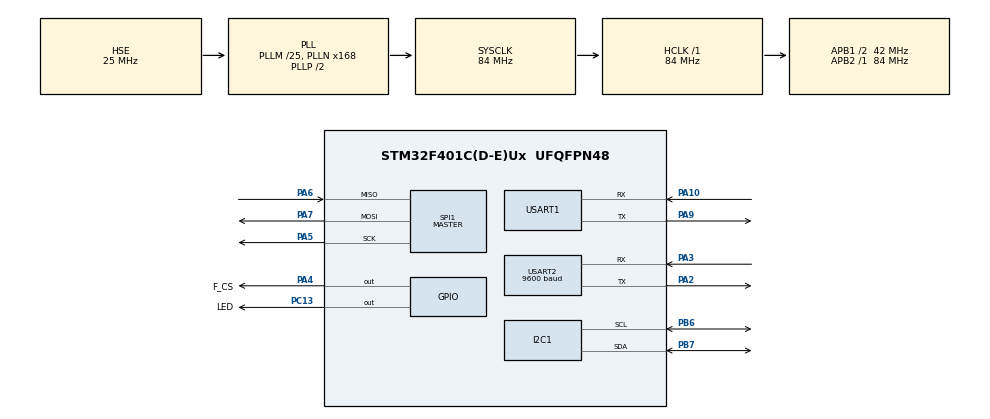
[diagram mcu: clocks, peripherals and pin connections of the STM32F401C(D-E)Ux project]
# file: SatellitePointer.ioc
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Dma.Request0=USART2_RX
Dma.USART2_RX.0.Direction=DMA_PERIPH_TO_MEMORY
Dma.USART2_RX.0.FIFOMode=DMA_FIFOMODE_DISABLE
Dma.USART2_RX.0.Instance=DMA1_Stream5
Dma.USART2_RX.0.MemDataAlignment=DMA_MDATAALIGN_BYTE
Dma.USART2_RX.0.MemInc=DMA_MINC_ENABLE
Dma.USART2_RX.0.Mode=DMA_NORMAL
Dma.USART2_RX.0.PeriphDataAlignment=DMA_PDATAALIGN_BYTE
Dma.USART2_RX.0.PeriphInc=DMA_PINC_DISABLE
Dma.USART2_RX.0.Priority=DMA_PRIORITY_LOW
FREERTOS.Tasks01=defaultTask,24,512,StartDefaultTask,Default,NULL,Dynamic,NULL,NULL;myTask01,8,256,StartTask01,Default,NULL,Dynamic,NULL,NULL;myTask02,8,256,StartTask02,Default,NULL,Dynamic,NULL,NULL
FREERTOS.Timers01=myTimer01,Callback01,osTimerPeriodic,Default,NULL,Dynamic,NULL;myTimer02,Callback02,osTimerPeriodic,Default,NULL,Dynamic,NULL;myTimer03,Callback03,osTimerPeriodic,Default,NULL,Dynamic,NULL;myTimer04,Callback04,osTimerPeriodic,Default,NULL,Dynamic,NULL
FREERTOS.configENABLE_FPU=1
FREERTOS.configMINIMAL_STACK_SIZE=256
FREERTOS.configTIMER_TASK_STACK_DEPTH=1024
FREERTOS.configUSE_NEWLIB_REENTRANT=1
I2C1.I2C_Mode=I2C_Fast
Mcu.Family=STM32F4
Mcu.Name=STM32F401C(D-E)Ux
Mcu.Package=UFQFPN48
NVIC.DMA1_Stream5_IRQn=true\:5\:0\:false\:false\:true\:true\:false\:true\:true
NVIC.PriorityGroup=NVIC_PRIORITYGROUP_4
NVIC.TIM1_UP_TIM10_IRQn=true\:15\:0\:false\:false\:true\:false\:false\:true\:true
NVIC.TimeBase=TIM1_UP_TIM10_IRQn
NVIC.TimeBaseIP=TIM1
NVIC.USART2_IRQn=true\:5\:0\:false\:false\:true\:true\:true\:true\:true
PA10.Mode=Asynchronous
PA10.Signal=USART1_RX
PA13.Mode=Serial_Wire
PA13.Signal=SYS_JTMS-SWDIO
PA14.Mode=Serial_Wire
PA14.Signal=SYS_JTCK-SWCLK
PA2.Mode=Asynchronous
PA2.Signal=USART2_TX
PA3.Mode=Asynchronous
PA3.Signal=USART2_RX
PA4.GPIO_Label=F_CS
PA4.GPIO_Speed=GPIO_SPEED_FREQ_VERY_HIGH
PA4.PinState=GPIO_PIN_RESET
PA4.Signal=GPIO_Output
PA5.Mode=Full_Duplex_Master
PA5.Signal=SPI1_SCK
PA6.Mode=Full_Duplex_Master
PA6.Signal=SPI1_MISO
PA7.Mode=Full_Duplex_Master
PA7.Signal=SPI1_MOSI
PA9.Mode=Asynchronous
PA9.Signal=USART1_TX
PB6.Mode=I2C
PB6.Signal=I2C1_SCL
PB7.Mode=I2C
PB7.Signal=I2C1_SDA
PC13-ANTI_TAMP.GPIO_Label=LED
PC13-ANTI_TAMP.Signal=GPIO_Output
PC14-OSC32_IN.Mode=LSE-External-Oscillator
PC14-OSC32_IN.Signal=RCC_OSC32_IN
PC15-OSC32_OUT.Mode=LSE-External-Oscillator
PC15-OSC32_OUT.Signal=RCC_OSC32_OUT
PH0\ -\ OSC_IN.Mode=HSE-External-Oscillator
PH0\ -\ OSC_IN.Signal=RCC_OSC_IN
PH1\ -\ OSC_OUT.Mode=HSE-External-Oscillator
PH1\ -\ OSC_OUT.Signal=RCC_OSC_OUT
ProjectManager.HeapSize=0x200
ProjectManager.StackSize=0x400
ProjectManager.TargetToolchain=STM32CubeIDE
RCC.48MHZClocksFreq_Value=42000000
RCC.AHBFreq_Value=84000000
RCC.APB1CLKDivider=RCC_HCLK_DIV2
RCC.APB1Freq_Value=42000000
RCC.APB1TimFreq_Value=84000000
RCC.APB2Freq_Value=84000000
RCC.APB2TimFreq_Value=84000000
RCC.CortexFreq_Value=84000000
RCC.HCLKFreq_Value=84000000
RCC.HSE_VALUE=25000000
RCC.HSI_VALUE=16000000
RCC.PLLM=25
RCC.PLLN=168
RCC.PLLSourceVirtual=RCC_PLLSOURCE_HSE
RCC.RCC_RTC_Clock_Source=RCC_RTCCLKSOURCE_LSE
RCC.RCC_RTC_Clock_SourceVirtual=RCC_RTCCLKSOURCE_LSE
RCC.SYSCLKFreq_VALUE=84000000
RCC.SYSCLKSource=RCC_SYSCLKSOURCE_PLLCLK
RCC.VCOOutputFreq_Value=168000000
SPI1.CLKPhase=SPI_PHASE_2EDGE
SPI1.CLKPolarity=SPI_POLARITY_HIGH
SPI1.Direction=SPI_DIRECTION_2LINES
SPI1.Mode=SPI_MODE_MASTER
SPI1.VirtualType=VM_MASTER
USART1.VirtualMode=VM_ASYNC
USART2.BaudRate=9600
USART2.VirtualMode=VM_ASYNC
VP_FREERTOS_VS_CMSIS_V2.Mode=CMSIS_V2
VP_RTC_VS_RTC_Activate.Mode=RTC_Enabled
VP_SYS_VS_tim1.Mode=TIM1
board=custom

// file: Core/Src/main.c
/* USER CODE BEGIN Header */
/**
  ******************************************************************************
  * @file           : main.c
  * @brief          : Main program body
  ******************************************************************************
  * @attention
  *
  * Copyright (c) 2023 STMicroelectronics.
  * All rights reserved.
  *
  * This software is licensed under terms that can be found in the LICENSE file
  * in the root directory of this software component.
  * If no LICENSE file comes with this software, it is provided AS-IS.
  *
  ******************************************************************************
  */
/* USER CODE END Header */
#include "main.h"
#include "cmsis_os.h"

I2C_HandleTypeDef hi2c1;

RTC_HandleTypeDef hrtc;

SPI_HandleTypeDef hspi1;

UART_HandleTypeDef huart1;
UART_HandleTypeDef huart2;
DMA_HandleTypeDef hdma_usart2_rx;

/* Definitions for defaultTask */
osThreadId_t defaultTaskHandle;
const osThreadAttr_t defaultTask_attributes = {
  .name = "defaultTask",
  .stack_size = 512 * 4,
  .priority = (osPriority_t) osPriorityNormal,
};
/* Definitions for myTask01 */
osThreadId_t myTask01Handle;
const osThreadAttr_t myTask01_attributes = {
  .name = "myTask01",
  .stack_size = 256 * 4,
  .priority = (osPriority_t) osPriorityLow,
};
/* Definitions for myTask02 */
osThreadId_t myTask02Handle;
const osThreadAttr_t myTask02_attributes = {
  .name = "myTask02",
  .stack_size = 256 * 4,
  .priority = (osPriority_t) osPriorityLow,
};
/* Definitions for myTimer01 */
osTimerId_t myTimer01Handle;
const osTimerAttr_t myTimer01_attributes = {
  .name = "myTimer01"
};
/* Definitions for myTimer02 */
osTimerId_t myTimer02Handle;
const osTimerAttr_t myTimer02_attributes = {
  .name = "myTimer02"
};
/* Definitions for myTimer03 */
osTimerId_t myTimer03Handle;
const osTimerAttr_t myTimer03_attributes = {
  .name = "myTimer03"
};
/* Definitions for myTimer04 */
osTimerId_t myTimer04Handle;
const osTimerAttr_t myTimer04_attributes = {
  .name = "myTimer04"
};

void SystemClock_Config(void);
static void MX_GPIO_Init(void);
static void MX_DMA_Init(void);
static void MX_I2C1_Init(void);
static void MX_SPI1_Init(void);
static void MX_USART1_UART_Init(void);
static void MX_USART2_UART_Init(void);
static void MX_RTC_Init(void);
void StartDefaultTask(void *argument);
void StartTask01(void *argument);
void StartTask02(void *argument);
void Callback01(void *argument);
void Callback02(void *argument);
void Callback03(void *argument);
void Callback04(void *argument);

int main(void)
{

  /* MCU Configuration--------------------------------------------------------*/

  /* Reset of all peripherals, Initializes the Flash interface and the Systick. */
  HAL_Init();

  /* Configure the system clock */
  SystemClock_Config();

  /* Initialize all configured peripherals */
  MX_GPIO_Init();
  MX_DMA_Init();
  MX_I2C1_Init();
  MX_SPI1_Init();
  MX_USART1_UART_Init();
  MX_USART2_UART_Init();
  MX_RTC_Init();

  /* Init scheduler */
  osKernelInitialize();

  /* Create the timer(s) */
  /* creation of myTimer01 */
  myTimer01Handle = osTimerNew(Callback01, osTimerPeriodic, NULL, &myTimer01_attributes);

  /* creation of myTimer02 */
  myTimer02Handle = osTimerNew(Callback02, osTimerPeriodic, NULL, &myTimer02_attributes);

  /* creation of myTimer03 */
  myTimer03Handle = osTimerNew(Callback03, osTimerPeriodic, NULL, &myTimer03_attributes);

  /* creation of myTimer04 */
  myTimer04Handle = osTimerNew(Callback04, osTimerPeriodic, NULL, &myTimer04_attributes);

  /* USER CODE BEGIN RTOS_TIMERS */
  /* start timers, add new ones, ... */
  osTimerStart(myTimer01Handle, 1000);
  osTimerStart(myTimer02Handle, 10);
  /* USER CODE END RTOS_TIMERS */

  /* Create the thread(s) */
  /* creation of defaultTask */
  defaultTaskHandle = osThreadNew(StartDefaultTask, NULL, &defaultTask_attributes);

  /* creation of myTask01 */
  myTask01Handle = osThreadNew(StartTask01, NULL, &myTask01_attributes);

  /* creation of myTask02 */
  myTask02Handle = osThreadNew(StartTask02, NULL, &myTask02_attributes);

  /* Start scheduler */
  osKernelStart();
  /* We should never get here as control is now taken by the scheduler */
  /* Infinite loop */
  while (1)
  {

  }
}

void SystemClock_Config(void)
{
  RCC_OscInitTypeDef RCC_OscInitStruct = {0};
  RCC_ClkInitTypeDef RCC_ClkInitStruct = {0};

  /** Configure the main internal regulator output voltage
  */
  __HAL_RCC_PWR_CLK_ENABLE();
  __HAL_PWR_VOLTAGESCALING_CONFIG(PWR_REGULATOR_VOLTAGE_SCALE2);

  /** Initializes the RCC Oscillators according to the specified parameters
  * in the RCC_OscInitTypeDef structure.
  */
  RCC_OscInitStruct.OscillatorType = RCC_OSCILLATORTYPE_HSE|RCC_OSCILLATORTYPE_LSE;
  RCC_OscInitStruct.HSEState = RCC_HSE_ON;
  RCC_OscInitStruct.LSEState = RCC_LSE_ON;
  RCC_OscInitStruct.PLL.PLLState = RCC_PLL_ON;
  RCC_OscInitStruct.PLL.PLLSource = RCC_PLLSOURCE_HSE;
  RCC_OscInitStruct.PLL.PLLM = 25;
  RCC_OscInitStruct.PLL.PLLN = 168;
  RCC_OscInitStruct.PLL.PLLP = RCC_PLLP_DIV2;
  RCC_OscInitStruct.PLL.PLLQ = 4;
  if (HAL_RCC_OscConfig(&RCC_OscInitStruct) != HAL_OK)
  {
    Error_Handler();
  }

  /** Initializes the CPU, AHB and APB buses clocks
  */
  RCC_ClkInitStruct.ClockType = RCC_CLOCKTYPE_HCLK|RCC_CLOCKTYPE_SYSCLK
                              |RCC_CLOCKTYPE_PCLK1|RCC_CLOCKTYPE_PCLK2;
  RCC_ClkInitStruct.SYSCLKSource = RCC_SYSCLKSOURCE_PLLCLK;
  RCC_ClkInitStruct.AHBCLKDivider = RCC_SYSCLK_DIV1;
  RCC_ClkInitStruct.APB1CLKDivider = RCC_HCLK_DIV2;
  RCC_ClkInitStruct.APB2CLKDivider = RCC_HCLK_DIV1;

  if (HAL_RCC_ClockConfig(&RCC_ClkInitStruct, FLASH_LATENCY_2) != HAL_OK)
  {
    Error_Handler();
  }
}

static void MX_I2C1_Init(void)
{

  hi2c1.Instance = I2C1;
  hi2c1.Init.ClockSpeed = 400000;
  hi2c1.Init.DutyCycle = I2C_DUTYCYCLE_2;
  hi2c1.Init.OwnAddress1 = 0;
  hi2c1.Init.AddressingMode = I2C_ADDRESSINGMODE_7BIT;
  hi2c1.Init.DualAddressMode = I2C_DUALADDRESS_DISABLE;
  hi2c1.Init.OwnAddress2 = 0;
  hi2c1.Init.GeneralCallMode = I2C_GENERALCALL_DISABLE;
  hi2c1.Init.NoStretchMode = I2C_NOSTRETCH_DISABLE;
  if (HAL_I2C_Init(&hi2c1) != HAL_OK)
  {
    Error_Handler();
  }

}

static void MX_RTC_Init(void)
{

  /** Initialize RTC Only
  */
  hrtc.Instance = RTC;
  hrtc.Init.HourFormat = RTC_HOURFORMAT_24;
  hrtc.Init.AsynchPrediv = 127;
  hrtc.Init.SynchPrediv = 255;
  hrtc.Init.OutPut = RTC_OUTPUT_DISABLE;
  hrtc.Init.OutPutPolarity = RTC_OUTPUT_POLARITY_HIGH;
  hrtc.Init.OutPutType = RTC_OUTPUT_TYPE_OPENDRAIN;
  if (HAL_RTC_Init(&hrtc) != HAL_OK)
  {
    Error_Handler();
  }

}

static void MX_SPI1_Init(void)
{

  /* SPI1 parameter configuration*/
  hspi1.Instance = SPI1;
  hspi1.Init.Mode = SPI_MODE_MASTER;
  hspi1.Init.Direction = SPI_DIRECTION_2LINES;
  hspi1.Init.DataSize = SPI_DATASIZE_8BIT;
  hspi1.Init.CLKPolarity = SPI_POLARITY_HIGH;
  hspi1.Init.CLKPhase = SPI_PHASE_2EDGE;
  hspi1.Init.NSS = SPI_NSS_SOFT;
  hspi1.Init.BaudRatePrescaler = SPI_BAUDRATEPRESCALER_2;
  hspi1.Init.FirstBit = SPI_FIRSTBIT_MSB;
  hspi1.Init.TIMode = SPI_TIMODE_DISABLE;
  hspi1.Init.CRCCalculation = SPI_CRCCALCULATION_DISABLE;
  hspi1.Init.CRCPolynomial = 10;
  if (HAL_SPI_Init(&hspi1) != HAL_OK)
  {
    Error_Handler();
  }

}

static void MX_USART1_UART_Init(void)
{

  huart1.Instance = USART1;
  huart1.Init.BaudRate = 115200;
  huart1.Init.WordLength = UART_WORDLENGTH_8B;
  huart1.Init.StopBits = UART_STOPBITS_1;
  huart1.Init.Parity = UART_PARITY_NONE;
  huart1.Init.Mode = UART_MODE_TX_RX;
  huart1.Init.HwFlowCtl = UART_HWCONTROL_NONE;
  huart1.Init.OverSampling = UART_OVERSAMPLING_16;
  if (HAL_UART_Init(&huart1) != HAL_OK)
  {
    Error_Handler();
  }

}

static void MX_USART2_UART_Init(void)
{

  huart2.Instance = USART2;
  huart2.Init.BaudRate = 9600;
  huart2.Init.WordLength = UART_WORDLENGTH_8B;
  huart2.Init.StopBits = UART_STOPBITS_1;
  huart2.Init.Parity = UART_PARITY_NONE;
  huart2.Init.Mode = UART_MODE_TX_RX;
  huart2.Init.HwFlowCtl = UART_HWCONTROL_NONE;
  huart2.Init.OverSampling = UART_OVERSAMPLING_16;
  if (HAL_UART_Init(&huart2) != HAL_OK)
  {
    Error_Handler();
  }

}

static void MX_DMA_Init(void)
{

  /* DMA controller clock enable */
  __HAL_RCC_DMA1_CLK_ENABLE();

  /* DMA interrupt init */
  /* DMA1_Stream5_IRQn interrupt configuration */
  HAL_NVIC_SetPriority(DMA1_Stream5_IRQn, 5, 0);
  HAL_NVIC_EnableIRQ(DMA1_Stream5_IRQn);

}

static void MX_GPIO_Init(void)
{
  GPIO_InitTypeDef GPIO_InitStruct = {0};

  /* GPIO Ports Clock Enable */
  __HAL_RCC_GPIOC_CLK_ENABLE();
  __HAL_RCC_GPIOH_CLK_ENABLE();
  __HAL_RCC_GPIOA_CLK_ENABLE();
  __HAL_RCC_GPIOB_CLK_ENABLE();

  /*Configure GPIO pin Output Level */
  HAL_GPIO_WritePin(LED_GPIO_Port, LED_Pin, GPIO_PIN_RESET);

  /*Configure GPIO pin Output Level */
  HAL_GPIO_WritePin(F_CS_GPIO_Port, F_CS_Pin, GPIO_PIN_RESET);

  /*Configure GPIO pin : LED_Pin */
  GPIO_InitStruct.Pin = LED_Pin;
  GPIO_InitStruct.Mode = GPIO_MODE_OUTPUT_PP;
  GPIO_InitStruct.Pull = GPIO_NOPULL;
  GPIO_InitStruct.Speed = GPIO_SPEED_FREQ_LOW;
  HAL_GPIO_Init(LED_GPIO_Port, &GPIO_InitStruct);

  /*Configure GPIO pin : F_CS_Pin */
  GPIO_InitStruct.Pin = F_CS_Pin;
  GPIO_InitStruct.Mode = GPIO_MODE_OUTPUT_PP;
  GPIO_InitStruct.Pull = GPIO_NOPULL;
  GPIO_InitStruct.Speed = GPIO_SPEED_FREQ_VERY_HIGH;
  HAL_GPIO_Init(F_CS_GPIO_Port, &GPIO_InitStruct);

}

void StartDefaultTask(void *argument)
{
  /* USER CODE BEGIN 5 */
  /* Infinite loop */
  for(;;)
  {
    osDelay(1000);
  }
  /* USER CODE END 5 */
}

void StartTask01(void *argument)
{
  /* USER CODE BEGIN StartTask01 */
  /* Infinite loop */
  for(;;)
  {
    osDelay(1000);
  }
  /* USER CODE END StartTask01 */
}

void StartTask02(void *argument)
{
  /* USER CODE BEGIN StartTask02 */
  /* Infinite loop */
  for(;;)
  {
    osDelay(1000);
  }
  /* USER CODE END StartTask02 */
}

/* Callback01 function */
void Callback01(void *argument)
{
  /* USER CODE BEGIN Callback01 */
    HAL_GPIO_WritePin(LED_GPIO_Port, LED_Pin, GPIO_PIN_RESET);
    osDelay(100L);
    HAL_GPIO_WritePin(LED_GPIO_Port, LED_Pin, GPIO_PIN_SET);
  /* USER CODE END Callback01 */
}

/* Callback02 function */
void Callback02(void *argument)
{
}

/* Callback03 function */
void Callback03(void *argument)
{
}

/* Callback04 function */
void Callback04(void *argument)
{
}

void HAL_TIM_PeriodElapsedCallback(TIM_HandleTypeDef *htim)
{
  if (htim->Instance == TIM1) {
    HAL_IncTick();
  }
}

void Error_Handler(void)
{
  __disable_irq();
  while (1)
  {
  }
}
